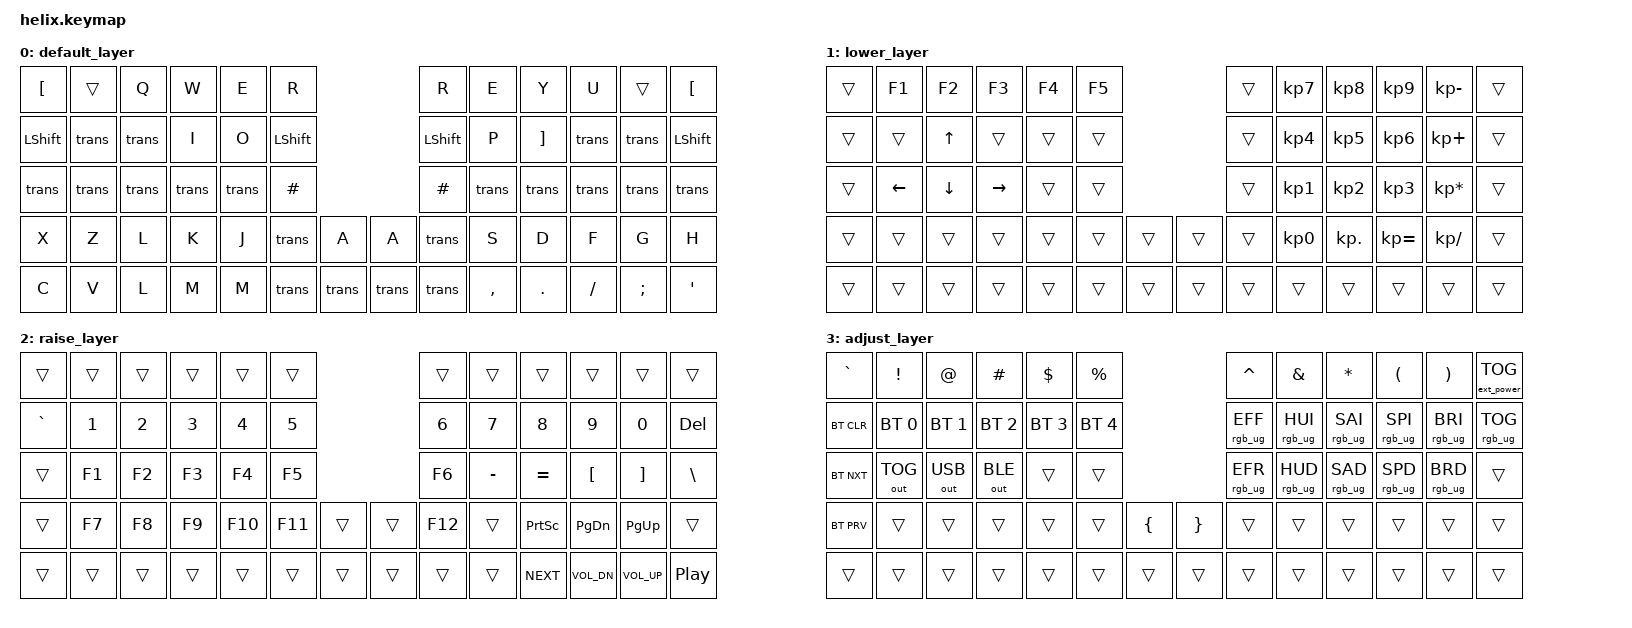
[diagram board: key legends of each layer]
/*
 * Copyright (c) 2020 The ZMK Contributors
 *
 * SPDX-License-Identifier: MIT
 */

 #include <behaviors.dtsi>
 #include <dt-bindings/zmk/keys.h>
 #include <dt-bindings/zmk/bt.h>
 #include <dt-bindings/zmk/rgb.h>
 #include <dt-bindings/zmk/ext_power.h>
 #include <dt-bindings/zmk/outputs.h>

 #define DEFAULT 0
 #define LOWER  1
 #define RAISE  2
 #define ADJUST 3

/* NOTE: At the time of the creation of this keymap, there are no specified codes for 'eisuu' and 'kana' input in ZMK.
However, 'LANG1' and 'LANG2' are fully-functioning candidates for 'kana' and 'eisuu' input respectively.
As such, those are in use within the default layer at this time.*/

/ {
       keymap {
              compatible = "zmk,keymap";

              default_layer {
  // ---------------------------------------------------------------------------------------------------------------------------------
  // |  LBKT  | &trans |   Q    |   W    |   E    |   R    |                                 |   R    |   E    |   Y    |   U    | &trans |  LBKT  |
  // |  LSHFT | $trans | $trans |   I    |   O    | LSHFT  |                                 | LSHFT  |   P    |   ]    | $trans | $trans |  LSHFT |
  // | $trans | $trans | $trans | $trans | $trans |   #    |                                 |   #    | $trans | $trans | $trans | $trans | $trans |
  // |   X    |   Z    |   L    |   K    |   J    | $trans |    A   |               |    A   | $trans |   S    |   D    |   F    |   G    |   H    |
  // |   C    |   V    |   B    |   M    |   N    | $trans | $trans |               | $trans | $trans |   ,    |   .    |   /    |   ;    |   '    |
                     bindings = <
       &kp LBKT  &trans  &kp Q    &kp W     &kp E    &kp R                                      &kp R    &kp E    &kp Y    &kp U   &trans  &kp LBKT
       &kp LSHFT $trans  $trans   &kp I     &kp O  &kp LSHFT                                  &kp LSHFT  &kp P   &kp RBKT  $trans  $trans  &kp LSHFT
        $trans   $trans  $trans   $trans   $trans  &kp HASH                                   &kp HASH  $trans   $trans    $trans  $trans   $trans
       &kp X    &kp Z    &kp L    &kp K    &kp J    $trans    &kp A                   &kp A     $trans   &kp S    &kp D    &kp F   &kp G   &kp H
       &kp C    &kp V    &kp L    &kp M    &kp M   $trans    $trans                  $trans     $trans &kp COMMA &kp PERIOD &kp FSLH &kp SEMI &kp SQT
                     >;
              };
              lower_layer {
  // ---------------------------------------------------------------------------------------------------------------------------------
  // |      |  F1  |  F2  |  F3   |  F4  |  F5  |                                  |      |  n7  |  n8  |  n9    | nminus |      |
  // |      |      |  UP  |       |      |      |                                  |      |  n4  |  n5  |  n6    | nplus  |      |
  // |      | LEFT | DOWN | RIGHT |      |      |                                  |      |  n1  |  n2  |  n3    | ntimes |      |
  // |      |      |      |      |      |      |      |                    |      |       |  n0  |  dot | nequal | ndiv   |      |
  // |      |      |      |      |      |      |      |                    |      |       |      |      |        |        |      |
                     bindings = <
       &trans    &kp F1   &kp F2 &kp F3   &kp F4   &kp F5                             &trans    &kp KP_N7    &kp KP_N8    &kp KP_N9   &kp KP_MINUS   &trans
       &trans &trans &kp UP &trans &trans &trans                          &trans &kp KP_N4  &kp KP_N5 &kp KP_N6 &kp KP_PLUS &trans
       &trans    &kp LEFT   &kp DOWN &kp RIGHT   &trans   &trans                             &trans    &kp KP_N1 &kp KP_N2  &kp KP_N3 &kp KP_ASTERISK &trans
       &trans    &trans   &trans &trans   &trans   &trans    &trans       &trans &trans    &kp KP_N0    &kp KP_DOT    &kp KP_EQUAL &kp KP_DIVIDE  &trans
       &trans    &trans   &trans &trans   &trans   &trans    &trans          &trans   &trans    &trans    &trans    &trans   &trans   &trans
                     >;
              };
              raise_layer {
 // ---------------------------------------------------------------------------------------------------------------------------------
 // |       |       |       |       |       |       |                                    |       |       |       |       |       |       |
 // |   `   |   1   |   2   |   3   |   4   |   5   |                                    |   6   |   7   |   8   |   9   |   0   |  DEL  |
 // |       |  F1   |  F2   |  F3   |  F4   |  F5   |                                    |  F6   |   -   |   =   |   [   |   ]   |   \   |
 // |       |  F7   |  F8   |  F9   |  F10  |  F11  |       |                    |       |  F12  |       | PSCRN | PG_DN | PG_UP |       |
 // |       |       |       |       |       |       |       |                    |       |       |       | NEXT  | VOL-  | VOL+  | PLAY  |
                     bindings = <
       &trans    &trans &trans &trans &trans  &trans                       &trans  &trans    &trans     &trans       &trans       &trans
       &kp GRAVE &kp N1 &kp N2 &kp N3 &kp N4  &kp N5                       &kp N6  &kp N7    &kp N8     &kp N9       &kp N0       &kp DEL
       &trans    &kp F1 &kp F2 &kp F3 &kp F4  &kp F5                       &kp F6  &kp MINUS &kp EQUAL  &kp LBKT     &kp RBKT     &kp BSLH
       &trans    &kp F7 &kp F8 &kp F9 &kp F10 &kp F11 &trans        &trans &kp F12 &trans    &kp PSCRN  &kp PG_DN    &kp PG_UP    &trans
       &trans    &trans &trans &trans &trans  &trans  &trans        &trans &trans  &trans    &kp C_NEXT &kp C_VOL_DN &kp C_VOL_UP &kp C_PP
                     >;
              };
              adjust_layer {
 // ---------------------------------------------------------------------------------------------------------------------------------
 // |    `     |    !     |    @     |    #     |    $     |    %     |                                          |    ^     |    &     |    *     |    (     |    )     |  EP TOG  |
 // |  BT CLR  | BT SEL0  | BT SEL1  | BT SEL2  | BGT SEL3 | BT SEL4  |                                          | RGB EFF+ | RGB HUE+ | RGB SAT+ | RGB SPD+ | RGB BRI+ | RGB TOG  |
 // |  BT NXT  | OUT TOG  | OUT USB  | OUT BLE  |          |          |                                          | RGB EFF- | RGB HUE- | RGB SAT- | RGB SPD- | RGB BRI- |          |
 // |  BT PRV  |          |          |          |          |          |    {     |                    |    }     |          |          |          |          |          |          |
 // |          |          |          |          |          |          |          |                    |          |          |          |          |          |          |          |
                     bindings = <
       &kp GRAVE  &kp EXCL     &kp AT       &kp HASH     &kp DLLR     &kp PRCNT                             &kp CARET       &kp AMPS        &kp ASTRK       &kp LPAR        &kp RPAR        &ext_power EP_TOG
       &bt BT_CLR &bt BT_SEL 0 &bt BT_SEL 1 &bt BT_SEL 2 &bt BT_SEL 3 &bt BT_SEL 4                          &rgb_ug RGB_EFF &rgb_ug RGB_HUI &rgb_ug RGB_SAI &rgb_ug RGB_SPI &rgb_ug RGB_BRI &rgb_ug RGB_TOG
       &bt BT_NXT &out OUT_TOG &out OUT_USB &out OUT_BLE &trans       &trans                                &rgb_ug RGB_EFR &rgb_ug RGB_HUD &rgb_ug RGB_SAD &rgb_ug RGB_SPD &rgb_ug RGB_BRD &trans
       &bt BT_PRV &trans       &trans       &trans       &trans       &trans       &kp LBRC        &kp RBRC &trans          &trans          &trans          &trans          &trans          &trans
       &trans     &trans       &trans       &trans       &trans       &trans       &trans          &trans   &trans          &trans          &trans          &trans          &trans          &trans
                     >;
              };
       };
};
